# MSP430F5529 register map
Vendor: msp430gen; File version: VERGEN_IDEMPOTENT_OUTPUT
Registers are 8-bit, read-write, reset 0x0 unless marked. A register's access mark holds for its fields unless they carry their own. Offsets are from the block's base; [hi:lo] are bit positions; {n}, {i} and the like mark numbered series.

## UCS — UCS Unified System Clock
Base 0x00000160
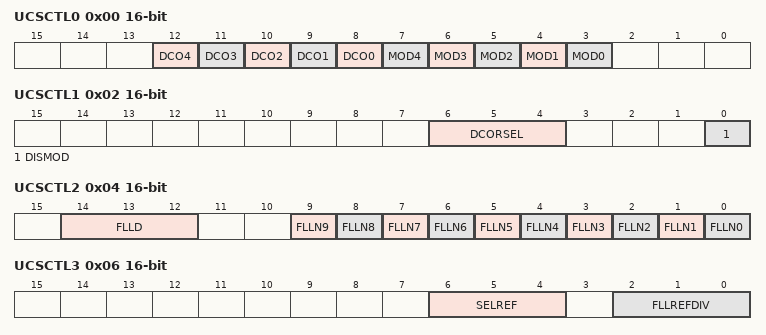
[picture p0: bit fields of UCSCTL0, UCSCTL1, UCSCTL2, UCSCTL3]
0x00 UCSCTL0 16-bit — UCS Control Register 0
  [n+8] DCO{n} (n=0..4) — DCO TAP Bit : {n}
  [n+3] MOD{n} (n=0..4) — Modulation Bit Counter Bit : {n}
0x02 UCSCTL1 16-bit — UCS Control Register 1
  [6:4] DCORSEL — DCO Freq. Range Select Bit : 0
  [0] DISMOD — Disable Modulation
0x04 UCSCTL2 16-bit — UCS Control Register 2
  [14:12] FLLD — Loop Divider Bit : 0
    0=Multiply Selected Loop Freq. 1; 1=Multiply Selected Loop Freq. 2; 2=Multiply Selected Loop Freq. 4; 3=Multiply Selected Loop Freq. 8; 4=Multiply Selected Loop Freq. 16; 5=Multiply Selected Loop Freq. 32; 6=Multiply Selected Loop Freq. 32; 7=Multiply Selected Loop Freq. 32
  [n] FLLN{n} (n=0..9) — FLL Multipier Bit : {n}
0x06 UCSCTL3 16-bit — UCS Control Register 3
  [6:4] SELREF — FLL Reference Clock Select Bit : 0
    {v}=FLL Reference Clock Select {v} (v=0..7)
  [2:0] FLLREFDIV — Reference Divider Bit : 0
    0=Reference Divider: f(LFCLK)/1; 1=Reference Divider: f(LFCLK)/2; 2=Reference Divider: f(LFCLK)/4; 3=Reference Divider: f(LFCLK)/8; 4=Reference Divider: f(LFCLK)/12; 5=Reference Divider: f(LFCLK)/16; 6=Reference Divider: f(LFCLK)/16; 7=Reference Divider: f(LFCLK)/16
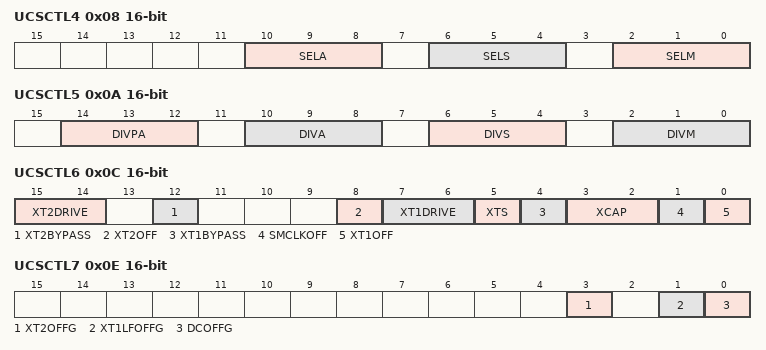
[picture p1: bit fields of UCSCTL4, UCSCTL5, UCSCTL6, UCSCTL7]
0x08 UCSCTL4 16-bit — UCS Control Register 4
  [10:8] SELA — ACLK Source Select Bit: 0
    {v}=ACLK Source Select {v} (v=0..7)
  [6:4] SELS — SMCLK Source Select Bit: 0
    {v}=SMCLK Source Select {v} (v=0..7)
  [2:0] SELM — MCLK Source Select Bit: 0
    {v}=MCLK Source Select {v} (v=0..7)
0x0A UCSCTL5 16-bit — UCS Control Register 5
  [14:12] DIVPA — ACLK from Pin Divider Bit: 0
    {v}=ACLK from Pin Source Divider {v} (v=0..7)
  [10:8] DIVA — ACLK Divider Bit: 0
    {v}=ACLK Source Divider {v} (v=0..7)
  [6:4] DIVS — SMCLK Divider Bit: 0
    {v}=SMCLK Source Divider {v} (v=0..7)
  [2:0] DIVM — MCLK Divider Bit: 0
    {v}=MCLK Source Divider {v} (v=0..7)
0x0C UCSCTL6 16-bit — UCS Control Register 6
  [15:14] XT2DRIVE — XT2 Drive Level mode Bit 0
    {v}=XT2 Drive Level mode: {v} (v=0..3)
  [12] XT2BYPASS — XT2 bypass mode : 0: internal 1:sourced from external pin
  [8] XT2OFF — High Frequency Oscillator 2 (XT2) disable
  [7:6] XT1DRIVE — XT1 Drive Level mode Bit 0
    {v}=XT1 Drive Level mode: {v} (v=0..3)
  [5] XTS — 1: Selects high-freq. oscillator
  [4] XT1BYPASS — XT1 bypass mode : 0: internal 1:sourced from external pin
  [3:2] XCAP — XIN/XOUT Cap Bit: 0
    {v}=XIN/XOUT Cap {v} (v=0..3)
  [1] SMCLKOFF
  [0] XT1OFF — High Frequency Oscillator 1 (XT1) disable
0x0E UCSCTL7 16-bit — UCS Control Register 7
  [3] XT2OFFG — High Frequency Oscillator 2 Fault Flag
  [1] XT1LFOFFG — XT1 Low Frequency Oscillator Fault Flag
  [0] DCOFFG — DCO Fault Flag
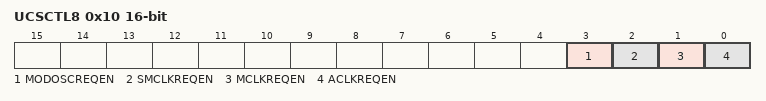
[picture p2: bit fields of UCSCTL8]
0x10 UCSCTL8 16-bit — UCS Control Register 8
  [3] MODOSCREQEN — MODOSC Clock Request Enable
  [2] SMCLKREQEN — SMCLK Clock Request Enable
  [1] MCLKREQEN — MCLK Clock Request Enable
  [0] ACLKREQEN — ACLK Clock Request Enable

## SYS — SYS System Module
Base 0x00000180
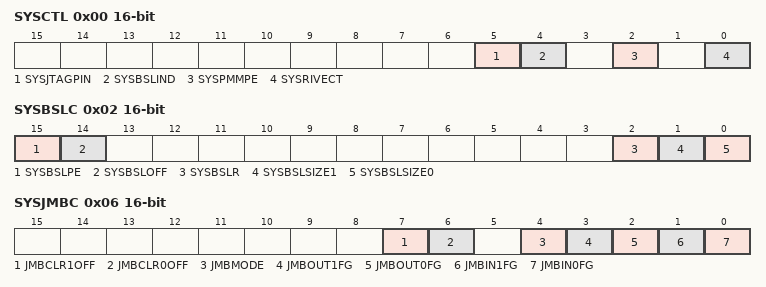
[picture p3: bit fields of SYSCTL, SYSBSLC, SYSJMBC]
0x00 SYSCTL 16-bit — System control
  [5] SYSJTAGPIN — SYS - Dedicated JTAG pins enabled
  [4] SYSBSLIND — SYS - TCK/RST indication detected
  [2] SYSPMMPE — SYS - PMM access protect
  [0] SYSRIVECT — SYS - RAM based interrupt vectors
0x02 SYSBSLC 16-bit — Boot strap configuration area
  [15] SYSBSLPE — SYS - BSL Memory protection enabled
  [14] SYSBSLOFF — SYS - BSL Memory disabled
  [2] SYSBSLR — SYS - RAM assigned to BSL
  [1] SYSBSLSIZE1 — SYS - BSL Protection Size 1
  [0] SYSBSLSIZE0 — SYS - BSL Protection Size 0
0x06 SYSJMBC 16-bit — JTAG mailbox control
  [7] JMBCLR1OFF — SYS - Incoming JTAG Mailbox 1 Flag auto-clear disalbe
  [6] JMBCLR0OFF — SYS - Incoming JTAG Mailbox 0 Flag auto-clear disalbe
  [4] JMBMODE — SYS - JMB 16/32 Bit Mode
  [3] JMBOUT1FG — SYS - Outgoing JTAG Mailbox 1 Flag
  [2] JMBOUT0FG — SYS - Outgoing JTAG Mailbox 0 Flag
  [1] JMBIN1FG — SYS - Incoming JTAG Mailbox 1 Flag
  [0] JMBIN0FG — SYS - Incoming JTAG Mailbox 0 Flag
0x08 SYSJMBI0 16-bit — JTAG mailbox input 0
0x0A SYSJMBI1 16-bit — JTAG mailbox input 1
0x0C SYSJMBO0 16-bit — JTAG mailbox output 0
0x0E SYSJMBO1 16-bit — JTAG mailbox output 1
0x18 SYSBERRIV 16-bit — Bus Error vector generator
0x1A SYSUNIV 16-bit — User NMI vector generator
0x1C SYSSNIV 16-bit — System NMI vector generator
0x1E SYSRSTIV 16-bit — Reset vector generator
